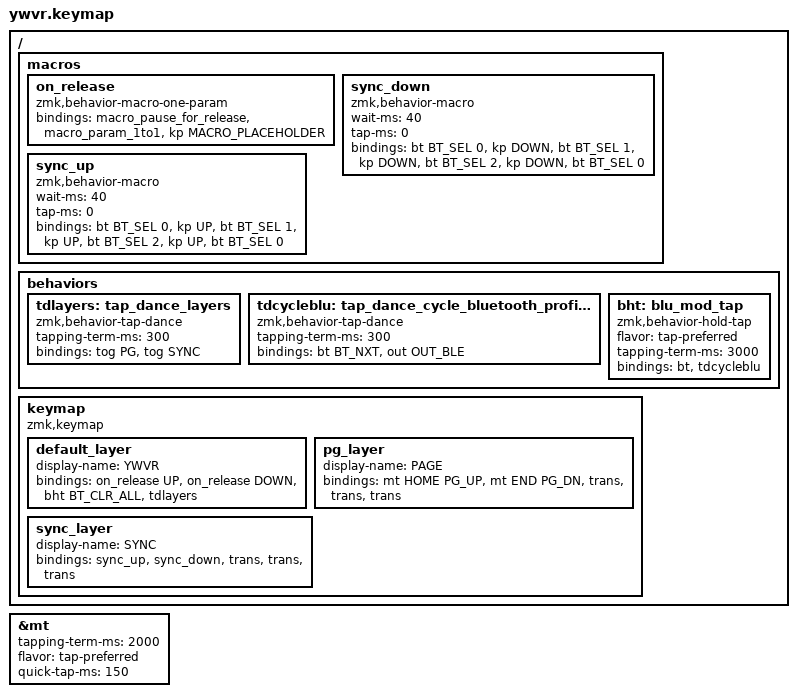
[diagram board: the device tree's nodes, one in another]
#include <behaviors.dtsi>
#include <dt-bindings/zmk/keys.h>
#include <dt-bindings/zmk/bt.h>
#include <dt-bindings/zmk/outputs.h>

#define DEFAULT 0
#define PG 1
#define SYNC 2


&mt {
    tapping-term-ms = <2000>; // This is the value already set by default
    flavor = "tap-preferred";
    quick-tap-ms = <150>;
};

/ {

  macros {


  on_release:on_release{
      compatible="zmk,behavior-macro-one-param";
#binding-cells =<1>;
      bindings=
	<&macro_pause_for_release>
	, <&macro_param_1to1>, <&kp MACRO_PLACEHOLDER>;
    };
    
  sync_down: sync_down {
      compatible = "zmk,behavior-macro";
      #binding-cells =<0>;
      wait-ms=<40>;
      tap-ms=<0>;
      bindings
	= <&bt BT_SEL 0>
	, <&kp DOWN>
	, <&bt BT_SEL 1>
	, <&kp DOWN>
	, <&bt BT_SEL 2>
	, <&kp DOWN>
	, <&bt BT_SEL 0>
	;
    };

  sync_up: sync_up {
      compatible = "zmk,behavior-macro";
      #binding-cells =<0>;
      wait-ms=<40>;
      tap-ms=<0>;
      bindings
	= <&bt BT_SEL 0>
	, <&kp UP>
	, <&bt BT_SEL 1>
	, <&kp UP>
	, <&bt BT_SEL 2>
	, <&kp UP>
	, <&bt BT_SEL 0>
	;
    };
  };

  behaviors {

  tdlayers: tap_dance_layers {
      compatible = "zmk,behavior-tap-dance";
      #binding-cells = <0>;
      tapping-term-ms = <300>;
      bindings = <&tog PG>, <&tog SYNC>;
      };  

  tdcycleblu: tap_dance_cycle_bluetooth_profile {
      compatible = "zmk,behavior-tap-dance";
      #binding-cells = <0>;
      tapping-term-ms = <300>;
      bindings = <&bt BT_NXT>, <&out OUT_BLE>;
    };


  bht: blu_mod_tap {
      compatible = "zmk,behavior-hold-tap";
      #binding-cells = <2>;
      flavor = "tap-preferred";
      tapping-term-ms = <3000>;
      bindings = <&bt >, <&tdcycleblu>;
    };

  };

  keymap {
    compatible = "zmk,keymap";
    
    default_layer { // default layer 0
      display-name = "YWVR";
      bindings = <
	&on_release UP &on_release DOWN &bht BT_CLR_ALL &tdlayers
	>;
    };

    pg_layer { // page layer 1 
      display-name="PAGE";
      bindings = <
	&mt HOME PG_UP &mt END PG_DN &trans &trans &trans
	>;
    };

    sync_layer { // sync layer 2
      display-name="SYNC";
      bindings = <
	&sync_up &sync_down &trans &trans &trans
	>;
    };
  };
};
